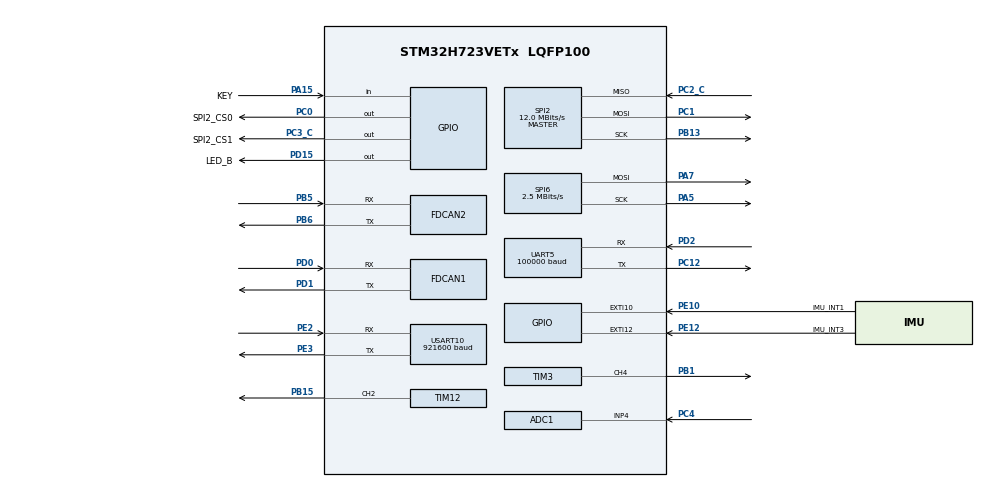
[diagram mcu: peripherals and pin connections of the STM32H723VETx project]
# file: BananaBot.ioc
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ADC1.Channel-0\#ChannelRegularConversion=ADC_CHANNEL_4
ADC1.ClockPrescaler=ADC_CLOCK_ASYNC_DIV64
ADC1.NbrOfConversionFlag=1
ADC1.OffsetNumber-0\#ChannelRegularConversion=ADC_OFFSET_NONE
ADC1.OffsetSignedSaturation-0\#ChannelRegularConversion=DISABLE
ADC1.Rank-0\#ChannelRegularConversion=1
ADC1.SamplingTime-0\#ChannelRegularConversion=ADC_SAMPLETIME_64CYCLES_5
ADC1.master=1
Bdma.Request0=SPI6_TX
Bdma.RequestsNb=1
Bdma.SPI6_TX.0.Direction=DMA_MEMORY_TO_PERIPH
Bdma.SPI6_TX.0.EventEnable=DISABLE
Bdma.SPI6_TX.0.Instance=BDMA_Channel0
Bdma.SPI6_TX.0.MemDataAlignment=DMA_MDATAALIGN_BYTE
Bdma.SPI6_TX.0.MemInc=DMA_MINC_ENABLE
Bdma.SPI6_TX.0.Mode=DMA_NORMAL
Bdma.SPI6_TX.0.PeriphDataAlignment=DMA_PDATAALIGN_BYTE
Bdma.SPI6_TX.0.PeriphInc=DMA_PINC_DISABLE
Bdma.SPI6_TX.0.Polarity=HAL_DMAMUX_REQ_GEN_RISING
Bdma.SPI6_TX.0.Priority=DMA_PRIORITY_LOW
Bdma.SPI6_TX.0.RequestNumber=1
Bdma.SPI6_TX.0.SignalID=NONE
Bdma.SPI6_TX.0.SyncEnable=DISABLE
Bdma.SPI6_TX.0.SyncPolarity=HAL_DMAMUX_SYNC_NO_EVENT
Bdma.SPI6_TX.0.SyncRequestNumber=1
Bdma.SPI6_TX.0.SyncSignalID=NONE
CORTEX_M7.CPU_DCache=Enabled
CORTEX_M7.CPU_ICache=Enabled
Dma.Request0=USART10_TX
Dma.Request1=UART5_RX
Dma.UART5_RX.1.Direction=DMA_PERIPH_TO_MEMORY
Dma.UART5_RX.1.EventEnable=DISABLE
Dma.UART5_RX.1.FIFOMode=DMA_FIFOMODE_DISABLE
Dma.UART5_RX.1.Instance=DMA1_Stream1
Dma.UART5_RX.1.MemDataAlignment=DMA_MDATAALIGN_BYTE
Dma.UART5_RX.1.MemInc=DMA_MINC_ENABLE
Dma.UART5_RX.1.Mode=DMA_NORMAL
Dma.UART5_RX.1.PeriphDataAlignment=DMA_PDATAALIGN_BYTE
Dma.UART5_RX.1.PeriphInc=DMA_PINC_DISABLE
Dma.UART5_RX.1.Polarity=HAL_DMAMUX_REQ_GEN_RISING
Dma.UART5_RX.1.Priority=DMA_PRIORITY_LOW
Dma.UART5_RX.1.RequestNumber=1
Dma.UART5_RX.1.SignalID=NONE
Dma.UART5_RX.1.SyncEnable=DISABLE
Dma.UART5_RX.1.SyncPolarity=HAL_DMAMUX_SYNC_NO_EVENT
Dma.UART5_RX.1.SyncRequestNumber=1
Dma.UART5_RX.1.SyncSignalID=NONE
Dma.USART10_TX.0.Direction=DMA_MEMORY_TO_PERIPH
Dma.USART10_TX.0.EventEnable=DISABLE
Dma.USART10_TX.0.FIFOMode=DMA_FIFOMODE_DISABLE
Dma.USART10_TX.0.Instance=DMA1_Stream0
Dma.USART10_TX.0.MemDataAlignment=DMA_MDATAALIGN_BYTE
Dma.USART10_TX.0.MemInc=DMA_MINC_ENABLE
Dma.USART10_TX.0.Mode=DMA_NORMAL
Dma.USART10_TX.0.PeriphDataAlignment=DMA_PDATAALIGN_BYTE
Dma.USART10_TX.0.PeriphInc=DMA_PINC_DISABLE
Dma.USART10_TX.0.Polarity=HAL_DMAMUX_REQ_GEN_RISING
Dma.USART10_TX.0.Priority=DMA_PRIORITY_LOW
Dma.USART10_TX.0.RequestNumber=1
Dma.USART10_TX.0.SignalID=NONE
Dma.USART10_TX.0.SyncEnable=DISABLE
Dma.USART10_TX.0.SyncPolarity=HAL_DMAMUX_SYNC_NO_EVENT
Dma.USART10_TX.0.SyncRequestNumber=1
Dma.USART10_TX.0.SyncSignalID=NONE
FDCAN1.CalculateBaudRateNominal=1000000
FDCAN1.CalculateTimeBitNominal=1000
FDCAN1.CalculateTimeQuantumNominal=166.66666666666666
FDCAN1.DataPrescaler=4
FDCAN1.DataTimeSeg1=3
FDCAN1.DataTimeSeg2=2
FDCAN1.MessageRAMOffset=0
FDCAN1.NominalPrescaler=4
FDCAN1.NominalSyncJumpWidth=1
FDCAN1.NominalTimeSeg1=3
FDCAN1.RxFifo0ElmtsNbr=32
FDCAN1.RxFifo1ElmtsNbr=0
FDCAN1.StdFiltersNbr=1
FDCAN1.TxFifoQueueElmtsNbr=6
FDCAN2.CalculateBaudRateNominal=1000000
FDCAN2.CalculateTimeBitNominal=1000
FDCAN2.CalculateTimeQuantumNominal=166.66666666666666
FDCAN2.DataPrescaler=4
FDCAN2.DataTimeSeg1=3
FDCAN2.DataTimeSeg2=2
FDCAN2.MessageRAMOffset=0x406
FDCAN2.NominalPrescaler=4
FDCAN2.NominalTimeSeg1=3
FDCAN2.NominalTimeSeg2=2
FDCAN2.RxFifo1ElmtsNbr=32
FDCAN2.StdFiltersNbr=1
FDCAN2.TxFifoQueueElmtsNbr=6
Mcu.Family=STM32H7
Mcu.Name=STM32H723VETx
Mcu.Package=LQFP100
NVIC.BDMA_Channel0_IRQn=true\:0\:0\:false\:false\:true\:true\:false\:true\:true
NVIC.DMA1_Stream0_IRQn=true\:0\:0\:false\:false\:true\:true\:false\:true\:true
NVIC.DMA1_Stream1_IRQn=true\:0\:0\:false\:false\:true\:true\:false\:true\:true
NVIC.EXTI15_10_IRQn=true\:0\:0\:false\:false\:false\:false\:true\:true\:false
NVIC.FDCAN1_IT0_IRQn=true\:0\:0\:false\:false\:true\:false\:true\:true\:true
NVIC.FDCAN1_IT1_IRQn=true\:0\:0\:false\:false\:true\:false\:true\:true\:true
NVIC.FDCAN2_IT0_IRQn=true\:0\:0\:false\:false\:true\:false\:true\:true\:true
NVIC.FDCAN2_IT1_IRQn=true\:0\:0\:false\:false\:true\:false\:true\:true\:true
NVIC.PriorityGroup=NVIC_PRIORITYGROUP_4
NVIC.SPI6_IRQn=true\:0\:0\:false\:false\:true\:false\:false\:true\:true
NVIC.TIM23_IRQn=true\:15\:0\:false\:false\:false\:false\:false\:true\:true
NVIC.TimeBase=TIM23_IRQn
NVIC.TimeBaseIP=TIM23
NVIC.UART5_IRQn=true\:0\:0\:false\:false\:true\:false\:true\:true\:true
NVIC.USART10_IRQn=true\:0\:0\:false\:false\:true\:false\:true\:true\:true
PA13(JTMS/SWDIO).Mode=Serial_Wire
PA13(JTMS/SWDIO).Signal=DEBUG_JTMS-SWDIO
PA14(JTCK/SWCLK).Mode=Serial_Wire
PA14(JTCK/SWCLK).Signal=DEBUG_JTCK-SWCLK
PA15(JTDI).GPIO_Label=KEY
PA15(JTDI).Signal=GPIO_Input
PA5.Mode=TX_Only_Simplex_Unidirect_Master
PA5.Signal=SPI6_SCK
PA7.Mode=TX_Only_Simplex_Unidirect_Master
PA7.Signal=SPI6_MOSI
PB1.Signal=S_TIM3_CH4
PB13.Mode=Full_Duplex_Master
PB13.Signal=SPI2_SCK
PB15.Signal=S_TIM12_CH2
PB5.Mode=FDCAN_Activate
PB5.Signal=FDCAN2_RX
PB6.Mode=FDCAN_Activate
PB6.Signal=FDCAN2_TX
PC0.GPIO_Label=SPI2_CS0
PC0.GPIO_Speed=GPIO_SPEED_FREQ_VERY_HIGH
PC0.PinState=GPIO_PIN_SET
PC0.Signal=GPIO_Output
PC1.Mode=Full_Duplex_Master
PC1.Signal=SPI2_MOSI
PC12.Mode=Asynchronous
PC12.Signal=UART5_TX
PC2_C.Mode=Full_Duplex_Master
PC2_C.Signal=SPI2_MISO
PC3_C.GPIO_Label=SPI2_CS1
PC3_C.GPIO_Speed=GPIO_SPEED_FREQ_VERY_HIGH
PC3_C.PinState=GPIO_PIN_SET
PC3_C.Signal=GPIO_Output
PC4.Signal=ADCx_INP4
PD0.Mode=FDCAN_Activate
PD0.Signal=FDCAN1_RX
PD1.Mode=FDCAN_Activate
PD1.Signal=FDCAN1_TX
PD15.GPIO_Label=LED_B
PD15.GPIO_Speed=GPIO_SPEED_FREQ_VERY_HIGH
PD15.PinState=GPIO_PIN_SET
PD15.Signal=GPIO_Output
PD2.Mode=Asynchronous
PD2.Signal=UART5_RX
PE10.GPIO_Label=IMU_INT1
PE10.Signal=GPXTI10
PE12.GPIO_Label=IMU_INT3
PE12.Signal=GPXTI12
PE2.Mode=Asynchronous
PE2.Signal=USART10_RX
PE3.Mode=Asynchronous
PE3.Signal=USART10_TX
PH0-OSC_IN.Mode=HSE-External-Oscillator
PH0-OSC_IN.Signal=RCC_OSC_IN
PH1-OSC_OUT.Mode=HSE-External-Oscillator
PH1-OSC_OUT.Signal=RCC_OSC_OUT
ProjectManager.HeapSize=0x200
ProjectManager.StackSize=0x400
ProjectManager.TargetToolchain=STM32CubeIDE
RCC.ADCCLockSelection=RCC_ADCCLKSOURCE_PLL3
RCC.ADCFreq_Value=96000000
RCC.APB1Freq_Value=137500000
RCC.APB2Freq_Value=137500000
RCC.APB3Freq_Value=137500000
RCC.APB4Freq_Value=137500000
RCC.CortexFreq_Value=550000000
RCC.D1PPRE=RCC_APB3_DIV2
RCC.D2PPRE1=RCC_APB1_DIV2
RCC.D2PPRE2=RCC_APB2_DIV2
RCC.D3PPRE=RCC_APB4_DIV2
RCC.DIVM1=3
RCC.DIVM2=4
RCC.DIVM3=2
RCC.DIVN1=68
RCC.DIVN2=80
RCC.DIVN3=16
RCC.DIVP1=1
RCC.DIVQ2=6
RCC.DIVQ3=3
RCC.FDCANCLockSelection=RCC_FDCANCLKSOURCE_HSE
RCC.HCLKFreq_Value=275000000
RCC.HPRE=RCC_HCLK_DIV2
RCC.HSE_VALUE=24000000
RCC.PLL1_VCI_Range=RCC_PLL1VCIRANGE_3
RCC.PLL3FRACN=0
RCC.PLLFRACN=6144
RCC.PLLSourceVirtual=RCC_PLLSOURCE_HSE
RCC.SPI123CLockSelection=RCC_SPI123CLKSOURCE_PLL3
RCC.SPI6CLockSelection=RCC_SPI6CLKSOURCE_PLL2
RCC.SYSCLKFreq_VALUE=550000000
RCC.SYSCLKSource=RCC_SYSCLKSOURCE_PLLCLK
RCC.USART16CLockSelection=RCC_USART16910CLKSOURCE_PLL3
RCC.USBCLockSelection=RCC_USBCLKSOURCE_HSI48
RCC.USBFreq_Value=48000000
SH.ADCx_INP4.0=ADC1_INP4,IN4-Single-Ended
SH.S_TIM12_CH2.0=TIM12_CH2,PWM Generation2 CH2
SH.S_TIM3_CH4.0=TIM3_CH4,PWM Generation4 CH4
SPI2.BaudRatePrescaler=SPI_BAUDRATEPRESCALER_8
SPI2.CalculateBaudRate=12.0 MBits/s
SPI2.DataSize=SPI_DATASIZE_8BIT
SPI2.Direction=SPI_DIRECTION_2LINES
SPI2.Mode=SPI_MODE_MASTER
SPI2.VirtualType=VM_MASTER
SPI6.BaudRatePrescaler=SPI_BAUDRATEPRESCALER_32
SPI6.CalculateBaudRate=2.5 MBits/s
SPI6.DataSize=SPI_DATASIZE_8BIT
SPI6.Direction=SPI_DIRECTION_2LINES_TXONLY
SPI6.Mode=SPI_MODE_MASTER
SPI6.VirtualType=VM_MASTER
STMicroelectronics.X-CUBE-AZRTOS-H7.3.2.0.TX_DISABLE_NOTIFY_CALLBACKS=1
STMicroelectronics.X-CUBE-AZRTOS-H7.3.2.0.TX_DISABLE_PREEMPTION_THRESHOLD=0
STMicroelectronics.X-CUBE-AZRTOS-H7.3.2.0.TX_DISABLE_REDUNDANT_CLEARING=1
STMicroelectronics.X-CUBE-AZRTOS-H7.3.2.0.TX_DISABLE_STACK_FILLING=1
STMicroelectronics.X-CUBE-AZRTOS-H7.3.2.0.TX_ENABLE_EVENT_TRACE=1
STMicroelectronics.X-CUBE-AZRTOS-H7.3.2.0.TX_ENABLE_STACK_CHECKING=0
STMicroelectronics.X-CUBE-AZRTOS-H7.3.2.0.TX_INLINE_THREAD_RESUME_SUSPEND=1
STMicroelectronics.X-CUBE-AZRTOS-H7.3.2.0.TX_REACTIVATE_INLINE=1
STMicroelectronics.X-CUBE-AZRTOS-H7.3.2.0.TX_TIMER_PROCESS_IN_ISR=1
STMicroelectronics.X-CUBE-AZRTOS-H7.3.2.0.TX_TIMER_TICKS_PER_SECOND=1000
STMicroelectronics.X-CUBE-AZRTOS-H7.3.2.0.ThreadXCcRTOSJjThreadXJjCore=true
STMicroelectronics.X-CUBE-AZRTOS-H7.3.2.0.ThreadXCcRTOSJjThreadXJjTraceXOosupport=true
STMicroelectronics.X-CUBE-AZRTOS-H7.3.2.0.USBD_CDCACM_EPINCMD_ADDR=2
STMicroelectronics.X-CUBE-AZRTOS-H7.3.2.0.USBD_PRODUCT_STRING=BananaBot
STMicroelectronics.X-CUBE-AZRTOS-H7.3.2.0.UX_SLAVE_REQUEST_DATA_MAX_LENGTH=512
STMicroelectronics.X-CUBE-AZRTOS-H7.3.2.0_IsAnAzureRtosMw=true
TIM12.Channel-PWM\ Generation2\ CH2=TIM_CHANNEL_2
TIM12.Period=99
TIM12.Prescaler=600
TIM3.Channel-PWM\ Generation4\ CH4=TIM_CHANNEL_4
TIM3.Period=999
TIM3.Prescaler=274
UART5.BaudRate=100000
UART5.Mode=MODE_RX
UART5.Parity=PARITY_EVEN
UART5.StopBits=UART_STOPBITS_2
UART5.WordLength=WORDLENGTH_9B
USART10.BaudRate=921600
USART10.VirtualMode=VM_ASYNC
VP_STMicroelectronics.X-CUBE-AZRTOS-H7_VS_RTOSJjThreadX_6.2.1_3.2.0.Mode=RTOSJjThreadX
VP_SYS_VS_tim23.Mode=TIM23
VP_TIM12_VS_ClockSourceINT.Mode=Internal
VP_TIM3_VS_ClockSourceINT.Mode=Internal
board=custom

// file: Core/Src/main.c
/* USER CODE BEGIN Header */
/**
  ******************************************************************************
  * @file           : main.c
  * @brief          : Main program body
  ******************************************************************************
  * @attention
  *
  * Copyright (c) 2024 STMicroelectronics.
  * All rights reserved.
  *
  * This software is licensed under terms that can be found in the LICENSE file
  * in the root directory of this software component.
  * If no LICENSE file comes with this software, it is provided AS-IS.
  *
  ******************************************************************************
  */
/* USER CODE END Header */
#include "app_threadx.h"
#include "main.h"
#include "adc.h"
#include "bdma.h"
#include "dma.h"
#include "fdcan.h"
#include "spi.h"
#include "tim.h"
#include "usart.h"
#include "gpio.h"

/* USER CODE BEGIN Includes */
#include "arm_math.h"
#include "stdarg.h"
#include "stdio.h"
/* USER CODE END Includes */

/* USER CODE BEGIN PM */
#define SRAM_SET_D2        __attribute__((section(".RAM_D2")))
/* USER CODE END PM */

/* USER CODE BEGIN PV */
//uint32_t fishPrintf(uint8_t *buf, const char *str, ...) {
//    va_list ap;
//    va_start(ap, str);
//    uint32_t len = vsnprintf((char *) buf, 512, str, ap);
//    va_end(ap);
//    return len;
//}
//
//void CANFilterConfig(void) {
//    FDCAN_FilterTypeDef Filter;
//    Filter.IdType = FDCAN_STANDARD_ID;
//    Filter.FilterIndex = 0;
//    Filter.FilterConfig = FDCAN_FILTER_TO_RXFIFO0;
//    Filter.FilterType = FDCAN_FILTER_MASK;
//    Filter.FilterID1 = 0x0000;
//    Filter.FilterID2 = 0x0000;
//
//    HAL_FDCAN_ConfigFilter(&hfdcan1, &Filter);
//    HAL_FDCAN_ActivateNotification(&hfdcan1, FDCAN_IT_RX_FIFO0_NEW_MESSAGE, 0);
//    HAL_FDCAN_ConfigGlobalFilter(&hfdcan1, FDCAN_REJECT, FDCAN_REJECT, FDCAN_REJECT_REMOTE, FDCAN_REJECT_REMOTE);
//
//    Filter.IdType = FDCAN_STANDARD_ID;
//    Filter.FilterIndex = 0;
//    Filter.FilterConfig = FDCAN_FILTER_TO_RXFIFO1;
//    Filter.FilterType = FDCAN_FILTER_MASK;
//    Filter.FilterID1 = 0x0000;
//    Filter.FilterID2 = 0x0000;
//
//    HAL_FDCAN_ConfigFilter(&hfdcan2, &Filter);
//    HAL_FDCAN_ActivateNotification(&hfdcan2, FDCAN_IT_RX_FIFO1_NEW_MESSAGE, 0);
//    HAL_FDCAN_ConfigGlobalFilter(&hfdcan2, FDCAN_REJECT, FDCAN_REJECT, FDCAN_REJECT_REMOTE, FDCAN_REJECT_REMOTE);
//
//    HAL_FDCAN_Start(&hfdcan1);
//    HAL_FDCAN_Start(&hfdcan2);
//}
//
//__PACKED_STRUCT  DM_Motor_t {
//    uint16_t pst;
//    int16_t rpm;
//    int16_t torque;
//    uint8_t tmp_coil;
//    uint8_t tmp_pcb;
//};
//
//SRAM_SET_D2 struct DM_Motor_t motor[4];
//SRAM_SET_D2 uint8_t RxData1[8];
//SRAM_SET_D2 uint8_t tx_buf[128];
//
//void HAL_FDCAN_RxFifo1Callback(FDCAN_HandleTypeDef *hfdcan, uint32_t RxFifo0ITs) {
//    FDCAN_RxHeaderTypeDef rx_header;
//    HAL_FDCAN_GetRxMessage(&hfdcan2, FDCAN_RX_FIFO1, &rx_header, RxData1);
//
//    switch (rx_header.Identifier) {
//        case 0x301:
//            motor[0].pst = RxData1[0] << 8 | RxData1[1];
//            motor[0].rpm = RxData1[2] << 8  | RxData1[3];
//            motor[0].torque = RxData1[4] << 8 | RxData1[5];
//            motor[0].tmp_coil = RxData1[6];
//            motor[0].tmp_pcb = RxData1[7];
//            break;
//        case 0x302:
//            motor[1].pst = RxData1[0] << 8 | RxData1[1];
//            motor[1].rpm = RxData1[2] << 8 | RxData1[3];
//            motor[1].torque = RxData1[4] << 8 | RxData1[5];
//            motor[1].tmp_coil = RxData1[6];
//            motor[1].tmp_pcb = RxData1[7];
//            break;
//        case 0x303:
//            motor[2].pst = RxData1[0] << 8 | RxData1[1];
//            motor[2].rpm = RxData1[2] << 8 | RxData1[3];
//            motor[2].torque = RxData1[4] << 8 | RxData1[5];
//            motor[2].tmp_coil = RxData1[6];
//            motor[2].tmp_pcb = RxData1[7];
//            break;
//        case 0x304:
//            motor[3].pst = RxData1[0] << 8 | RxData1[1];
//            motor[3].rpm = RxData1[2] << 8 | RxData1[3];
//            motor[3].torque = RxData1[4] << 8 | RxData1[5];
//            motor[3].tmp_coil = RxData1[6];
//            motor[3].tmp_pcb = RxData1[7];
//            break;
//        default:
//            break;
//    }
//}
/* USER CODE END PV */

void SystemClock_Config(void);
void PeriphCommonClock_Config(void);

int main(void)
{

  /* Enable the CPU Cache */

  /* Enable I-Cache---------------------------------------------------------*/
  SCB_EnableICache();

  /* Enable D-Cache---------------------------------------------------------*/
  SCB_EnableDCache();

  /* MCU Configuration--------------------------------------------------------*/

  /* Reset of all peripherals, Initializes the Flash interface and the Systick. */
  HAL_Init();

  /* Configure the system clock */
  SystemClock_Config();

/* Configure the peripherals common clocks */
  PeriphCommonClock_Config();

  /* Initialize all configured peripherals */
  MX_GPIO_Init();
  MX_BDMA_Init();
  MX_DMA_Init();
  MX_FDCAN2_Init();
  MX_SPI2_Init();
  MX_SPI6_Init();
  MX_TIM12_Init();
  MX_ADC1_Init();
  MX_USART10_UART_Init();
  MX_FDCAN1_Init();
  MX_TIM3_Init();
  MX_UART5_Init();
  /* USER CODE BEGIN 2 */
//
//    CANFilterConfig();
//    FDCAN_TxHeaderTypeDef TxHeader1 = {0};
//    TxHeader1.BitRateSwitch = FDCAN_BRS_OFF;
//    TxHeader1.FDFormat = FDCAN_CLASSIC_CAN;
//    TxHeader1.Identifier = 0x3FE;
//    TxHeader1.IdType = FDCAN_STANDARD_ID;
//    TxHeader1.DataLength = FDCAN_DLC_BYTES_8;
//    TxHeader1.TxFrameType = FDCAN_DATA_FRAME;
//
//    uint8_t data_tx[8] = {0};
//    uint8_t data_tx_zero[8] = {0};
//    data_tx[0] = (-100)>>8;
//    data_tx[1] = (-100)&0xFF;
//    data_tx[2] = (100)>>8;
//    data_tx[3] = (100)&0xFF;
//    data_tx[4] = (100)>>8;
//    data_tx[5] = (100)&0xFF;
//    data_tx[6] = (-100)>>8;
//    data_tx[7] = (-100)&0xFF;
  /* USER CODE END 2 */

  MX_ThreadX_Init();

  /* We should never get here as control is now taken by the scheduler */

  /* Infinite loop */
    while (1) {

    /* USER CODE BEGIN 3 */
//        HAL_GPIO_TogglePin(LED_B_GPIO_Port, LED_B_Pin);
//        uint16_t len = fishPrintf(tx_buf, "pst0=%d, rpm0=%d, tqr0=%d\r\n", motor[0].pst, motor[0].rpm, motor[0].torque);
//        SCB_CleanInvalidateDCache_by_Addr((uint32_t *) tx_buf, len);
//        HAL_UART_Transmit_DMA(&huart1, tx_buf, len);
//        HAL_Delay(10);
//        HAL_GPIO_TogglePin(LED_B_GPIO_Port, LED_B_Pin);
//        len = fishPrintf(tx_buf, "pst1=%d, rpm1=%d, tqr1=%d\r\n", motor[1].pst, motor[1].rpm, motor[1].torque);
//        SCB_CleanInvalidateDCache_by_Addr((uint32_t *) tx_buf, len);
//        HAL_UART_Transmit_DMA(&huart1, tx_buf, len);
//        HAL_Delay(10);
//        if(HAL_GPIO_ReadPin(KEY_GPIO_Port,KEY_Pin) == GPIO_PIN_RESET){
//            HAL_FDCAN_AddMessageToTxFifoQ(&hfdcan2, &TxHeader1, data_tx);
//        }else{
//            HAL_FDCAN_AddMessageToTxFifoQ(&hfdcan2, &TxHeader1, data_tx_zero);
//        }
    }
  /* USER CODE END 3 */
}

void SystemClock_Config(void)
{
  RCC_OscInitTypeDef RCC_OscInitStruct = {0};
  RCC_ClkInitTypeDef RCC_ClkInitStruct = {0};

  /** Supply configuration update enable
  */
  HAL_PWREx_ConfigSupply(PWR_LDO_SUPPLY);

  /** Configure the main internal regulator output voltage
  */
  __HAL_PWR_VOLTAGESCALING_CONFIG(PWR_REGULATOR_VOLTAGE_SCALE0);

  while(!__HAL_PWR_GET_FLAG(PWR_FLAG_VOSRDY)) {}

  /** Initializes the RCC Oscillators according to the specified parameters
  * in the RCC_OscInitTypeDef structure.
  */
  RCC_OscInitStruct.OscillatorType = RCC_OSCILLATORTYPE_HSE;
  RCC_OscInitStruct.HSEState = RCC_HSE_ON;
  RCC_OscInitStruct.PLL.PLLState = RCC_PLL_ON;
  RCC_OscInitStruct.PLL.PLLSource = RCC_PLLSOURCE_HSE;
  RCC_OscInitStruct.PLL.PLLM = 3;
  RCC_OscInitStruct.PLL.PLLN = 68;
  RCC_OscInitStruct.PLL.PLLP = 1;
  RCC_OscInitStruct.PLL.PLLQ = 2;
  RCC_OscInitStruct.PLL.PLLR = 2;
  RCC_OscInitStruct.PLL.PLLRGE = RCC_PLL1VCIRANGE_3;
  RCC_OscInitStruct.PLL.PLLVCOSEL = RCC_PLL1VCOWIDE;
  RCC_OscInitStruct.PLL.PLLFRACN = 6144;
  if (HAL_RCC_OscConfig(&RCC_OscInitStruct) != HAL_OK)
  {
    Error_Handler();
  }

  /** Initializes the CPU, AHB and APB buses clocks
  */
  RCC_ClkInitStruct.ClockType = RCC_CLOCKTYPE_HCLK|RCC_CLOCKTYPE_SYSCLK
                              |RCC_CLOCKTYPE_PCLK1|RCC_CLOCKTYPE_PCLK2
                              |RCC_CLOCKTYPE_D3PCLK1|RCC_CLOCKTYPE_D1PCLK1;
  RCC_ClkInitStruct.SYSCLKSource = RCC_SYSCLKSOURCE_PLLCLK;
  RCC_ClkInitStruct.SYSCLKDivider = RCC_SYSCLK_DIV1;
  RCC_ClkInitStruct.AHBCLKDivider = RCC_HCLK_DIV2;
  RCC_ClkInitStruct.APB3CLKDivider = RCC_APB3_DIV2;
  RCC_ClkInitStruct.APB1CLKDivider = RCC_APB1_DIV2;
  RCC_ClkInitStruct.APB2CLKDivider = RCC_APB2_DIV2;
  RCC_ClkInitStruct.APB4CLKDivider = RCC_APB4_DIV2;

  if (HAL_RCC_ClockConfig(&RCC_ClkInitStruct, FLASH_LATENCY_3) != HAL_OK)
  {
    Error_Handler();
  }
}

void PeriphCommonClock_Config(void)
{
  RCC_PeriphCLKInitTypeDef PeriphClkInitStruct = {0};

  /** Initializes the peripherals clock
  */
  PeriphClkInitStruct.PeriphClockSelection = RCC_PERIPHCLK_ADC|RCC_PERIPHCLK_SPI2
                              |RCC_PERIPHCLK_USART10;
  PeriphClkInitStruct.PLL3.PLL3M = 2;
  PeriphClkInitStruct.PLL3.PLL3N = 16;
  PeriphClkInitStruct.PLL3.PLL3P = 2;
  PeriphClkInitStruct.PLL3.PLL3Q = 3;
  PeriphClkInitStruct.PLL3.PLL3R = 2;
  PeriphClkInitStruct.PLL3.PLL3RGE = RCC_PLL3VCIRANGE_3;
  PeriphClkInitStruct.PLL3.PLL3VCOSEL = RCC_PLL3VCOWIDE;
  PeriphClkInitStruct.PLL3.PLL3FRACN = 0;
  PeriphClkInitStruct.Spi123ClockSelection = RCC_SPI123CLKSOURCE_PLL3;
  PeriphClkInitStruct.Usart16ClockSelection = RCC_USART16910CLKSOURCE_PLL3;
  PeriphClkInitStruct.AdcClockSelection = RCC_ADCCLKSOURCE_PLL3;
  if (HAL_RCCEx_PeriphCLKConfig(&PeriphClkInitStruct) != HAL_OK)
  {
    Error_Handler();
  }
}

/* USER CODE BEGIN 4 */
void TIM23_IRQHandler() {
    HAL_IncTick();
    LL_TIM_ClearFlag_UPDATE(TIM23);
}
/* USER CODE END 4 */

void HAL_TIM_PeriodElapsedCallback(TIM_HandleTypeDef *htim)
{
  if (htim->Instance == TIM23) {
    HAL_IncTick();
  }
}

void Error_Handler(void)
{
    __disable_irq();
    while (1) {
    }
}
